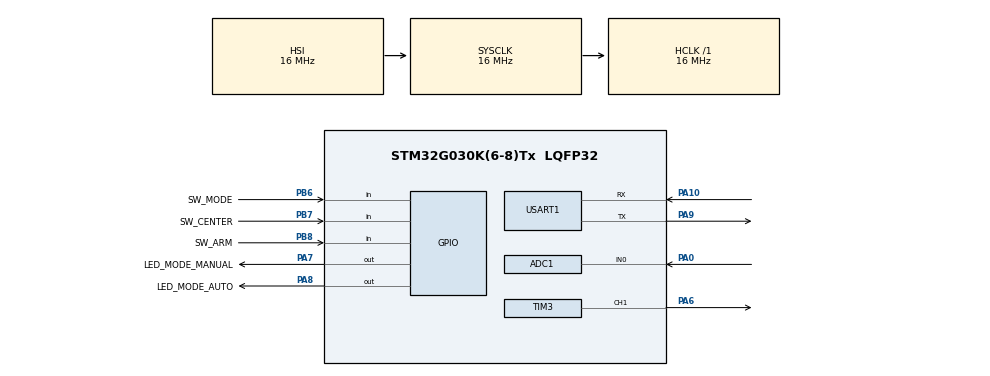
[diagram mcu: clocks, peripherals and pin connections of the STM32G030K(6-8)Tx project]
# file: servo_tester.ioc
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ADC1.Channel-0\#ChannelRegularConversion=ADC_CHANNEL_0
ADC1.NbrOfConversionFlag=1
ADC1.OversamplingMode=ENABLE
ADC1.Rank-0\#ChannelRegularConversion=1
ADC1.SamplingTime-0\#ChannelRegularConversion=ADC_SAMPLINGTIME_COMMON_1
ADC1.SamplingTimeCommon1=ADC_SAMPLETIME_160CYCLES_5
ADC1.SamplingTimeCommon2=ADC_SAMPLETIME_160CYCLES_5
ADC1.SelectedChannel=ADC_CHANNEL_0
ADC1.master=1
Mcu.Family=STM32G0
Mcu.Name=STM32G030K(6-8)Tx
Mcu.Package=LQFP32
PA0.Mode=IN0
PA0.Signal=ADC1_IN0
PA10.Mode=Asynchronous
PA10.Signal=USART1_RX
PA13.Mode=Serial_Wire
PA13.Signal=SYS_SWDIO
PA14-BOOT0.Mode=Serial_Wire
PA14-BOOT0.Signal=SYS_SWCLK
PA6.Signal=S_TIM3_CH1
PA7.GPIO_Label=LED_MODE_MANUAL
PA7.Signal=GPIO_Output
PA8.GPIO_Label=LED_MODE_AUTO
PA8.Signal=GPIO_Output
PA9.Mode=Asynchronous
PA9.Signal=USART1_TX
PB6.GPIO_Label=SW_MODE
PB6.GPIO_PuPd=GPIO_PULLUP
PB6.Signal=GPIO_Input
PB7.GPIO_Label=SW_CENTER
PB7.GPIO_PuPd=GPIO_PULLUP
PB7.Signal=GPIO_Input
PB8.GPIO_Label=SW_ARM
PB8.GPIO_PuPd=GPIO_PULLUP
PB8.Signal=GPIO_Input
ProjectManager.HeapSize=0x200
ProjectManager.StackSize=0x400
ProjectManager.TargetToolchain=STM32CubeIDE
RCC.AHBFreq_Value=16000000
RCC.CortexFreq_Value=16000000
RCC.EXTERNAL_CLOCK_VALUE=12288000
RCC.HCLKFreq_Value=16000000
RCC.HSE_VALUE=8000000
RCC.HSI_VALUE=16000000
RCC.LSE_VALUE=32768
RCC.SYSCLKFreq_VALUE=16000000
RCC.VCOOutputFreq_Value=128000000
SH.S_TIM3_CH1.0=TIM3_CH1,PWM Generation1 CH1
TIM3.Channel-PWM\ Generation1\ CH1=TIM_CHANNEL_1
TIM3.Period=19999
TIM3.Prescaler=15
TIM3.Pulse-PWM\ Generation1\ CH1=1499
USART1.VirtualMode-Asynchronous=VM_ASYNC
VP_TIM3_VS_ClockSourceINT.Mode=Internal
board=custom

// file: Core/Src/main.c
/* USER CODE BEGIN Header */
/**
  ******************************************************************************
  * @file           : main.c
  * @brief          : Main program body
  ******************************************************************************
  * @attention
  *
  * Copyright (c) 2026 STMicroelectronics.
  * All rights reserved.
  *
  * This software is licensed under terms that can be found in the LICENSE file
  * in the root directory of this software component.
  * If no LICENSE file comes with this software, it is provided AS-IS.
  *
  ******************************************************************************
  */
/* USER CODE END Header */
#include "main.h"
#include "adc.h"
#include "tim.h"
#include "usart.h"
#include "gpio.h"

/* USER CODE BEGIN Includes */
#include "mode_fsm.h"
#include "buttons.h"
#include "led.h"
#include <stdbool.h>
/* USER CODE END Includes */

void SystemClock_Config(void);

int main(void)
{

  /* MCU Configuration--------------------------------------------------------*/

  /* Reset of all peripherals, Initializes the Flash interface and the Systick. */
  HAL_Init();

  /* Configure the system clock */
  SystemClock_Config();

  /* Initialize all configured peripherals */
  MX_GPIO_Init();
  MX_ADC1_Init();
  MX_TIM3_Init();
  MX_USART1_UART_Init();
  /* USER CODE BEGIN 2 */
  fsm_init();
  /* USER CODE END 2 */

  /* Infinite loop */
  while (1)
  {

	  if (button_get(BTN_MODE)) led_pattern_select(LED_AUTO, LED_SLOW_BLINK);

	  if (button_get(BTN_CENTER)) led_pattern_select(LED_AUTO, LED_FAST_BLINK_x2);

	  if (button_get(BTN_ARM)) led_pattern_select(LED_AUTO, LED_FAST_BLINK);

	  led_update();

  }
}

void SystemClock_Config(void)
{
  RCC_OscInitTypeDef RCC_OscInitStruct = {0};
  RCC_ClkInitTypeDef RCC_ClkInitStruct = {0};

  /** Configure the main internal regulator output voltage
  */
  HAL_PWREx_ControlVoltageScaling(PWR_REGULATOR_VOLTAGE_SCALE1);

  /** Initializes the RCC Oscillators according to the specified parameters
  * in the RCC_OscInitTypeDef structure.
  */
  RCC_OscInitStruct.OscillatorType = RCC_OSCILLATORTYPE_HSI;
  RCC_OscInitStruct.HSIState = RCC_HSI_ON;
  RCC_OscInitStruct.HSIDiv = RCC_HSI_DIV1;
  RCC_OscInitStruct.HSICalibrationValue = RCC_HSICALIBRATION_DEFAULT;
  RCC_OscInitStruct.PLL.PLLState = RCC_PLL_NONE;
  if (HAL_RCC_OscConfig(&RCC_OscInitStruct) != HAL_OK)
  {
    Error_Handler();
  }

  /** Initializes the CPU, AHB and APB buses clocks
  */
  RCC_ClkInitStruct.ClockType = RCC_CLOCKTYPE_HCLK|RCC_CLOCKTYPE_SYSCLK
                              |RCC_CLOCKTYPE_PCLK1;
  RCC_ClkInitStruct.SYSCLKSource = RCC_SYSCLKSOURCE_HSI;
  RCC_ClkInitStruct.AHBCLKDivider = RCC_SYSCLK_DIV1;
  RCC_ClkInitStruct.APB1CLKDivider = RCC_HCLK_DIV1;

  if (HAL_RCC_ClockConfig(&RCC_ClkInitStruct, FLASH_LATENCY_0) != HAL_OK)
  {
    Error_Handler();
  }
}

void Error_Handler(void)
{
  __disable_irq();
  while (1)
  {
  }
}
